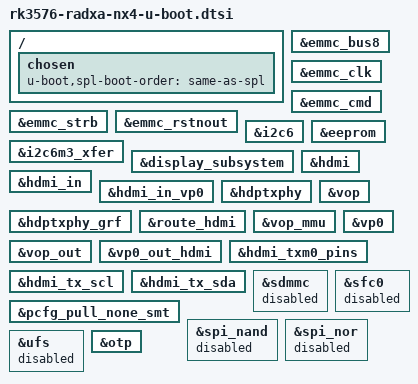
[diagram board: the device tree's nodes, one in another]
// SPDX-License-Identifier: (GPL-2.0+ OR MIT)
#include <dt-bindings/input/input.h>
#include "rk3576-u-boot.dtsi"

/ {
	chosen {
		u-boot,spl-boot-order = &sdhci, "same-as-spl";
	};
};

&emmc_bus8 {
	bootph-all;
};

&emmc_clk {
	bootph-all;
};

&emmc_cmd {
	bootph-all;
};

&emmc_strb {
	bootph-all;
};

&emmc_rstnout {
	bootph-all;
};

&i2c6 {
	bootph-all;
};

&i2c6m3_xfer {
	bootph-all;
};

&eeprom {
	bootph-all;
};

&display_subsystem {
	bootph-all;
};

&hdmi {
	bootph-all;
};

&hdmi_in {
	bootph-all;
};

&hdmi_in_vp0 {
	bootph-all;
};

&hdptxphy {
	bootph-all;
};

&hdptxphy_grf {
	bootph-all;
};

&route_hdmi {
	bootph-all;
};

&vop {
	bootph-all;
};

&vop_mmu {
	bootph-all;
};

&vop_out {
	bootph-all;
};

&vp0 {
	bootph-all;
};

&vp0_out_hdmi {
	bootph-all;
};

&hdmi_txm0_pins {
	bootph-all;
};

&hdmi_tx_scl {
	bootph-all;
};

&hdmi_tx_sda {
	bootph-all;
};

&pcfg_pull_none_smt {
	bootph-all;
};

&sdmmc {
	status = "disabled";
};

&sfc0 {
	status = "disabled";
};

&spi_nand {
	status = "disabled";
};

&spi_nor {
	status = "disabled";
};

&ufs {
	status = "disabled";
};

&otp {
	bootph-all;
	status = "okay";
};
